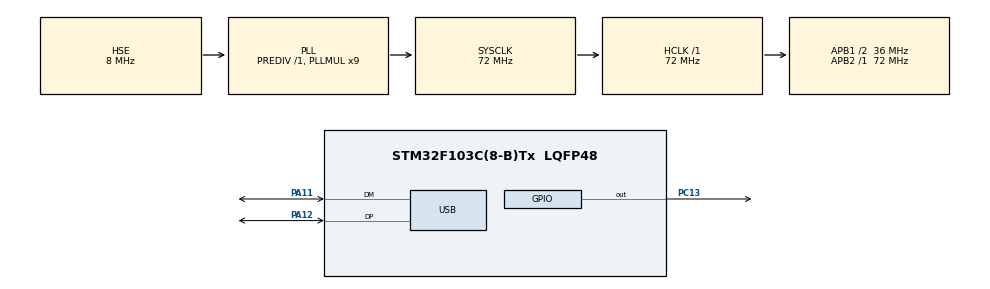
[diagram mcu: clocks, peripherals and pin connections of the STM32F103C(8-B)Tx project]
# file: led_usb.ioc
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FREERTOS.Queues01=receiveQueue,2,128,1,Dynamic,NULL,NULL
FREERTOS.Tasks01=defaultTask,24,128,StartDefaultTask,Default,NULL,Dynamic,NULL,NULL;Taskcmd,24,512,StartTaskcmd,Default,NULL,Dynamic,NULL,NULL
FREERTOS.configTOTAL_HEAP_SIZE=4000
Mcu.Family=STM32F1
Mcu.Name=STM32F103C(8-B)Tx
Mcu.Package=LQFP48
NVIC.PriorityGroup=NVIC_PRIORITYGROUP_4
NVIC.TIM1_UP_IRQn=true\:15\:0\:false\:false\:true\:false\:false\:true\:true
NVIC.TimeBase=TIM1_UP_IRQn
NVIC.TimeBaseIP=TIM1
NVIC.USB_LP_CAN1_RX0_IRQn=true\:5\:0\:false\:false\:true\:true\:false\:true\:true
PA11.Mode=Device
PA11.Signal=USB_DM
PA12.Mode=Device
PA12.Signal=USB_DP
PC13-TAMPER-RTC.Signal=GPIO_Output
PD0-OSC_IN.Mode=HSE-External-Oscillator
PD0-OSC_IN.Signal=RCC_OSC_IN
PD1-OSC_OUT.Mode=HSE-External-Oscillator
PD1-OSC_OUT.Signal=RCC_OSC_OUT
ProjectManager.HeapSize=0x200
ProjectManager.StackSize=0x400
ProjectManager.TargetToolchain=STM32CubeIDE
RCC.AHBFreq_Value=72000000
RCC.APB1CLKDivider=RCC_HCLK_DIV2
RCC.APB1Freq_Value=36000000
RCC.APB1TimFreq_Value=72000000
RCC.APB2Freq_Value=72000000
RCC.APB2TimFreq_Value=72000000
RCC.HCLKFreq_Value=72000000
RCC.PLLMUL=RCC_PLL_MUL9
RCC.SYSCLKFreq_VALUE=72000000
RCC.SYSCLKSource=RCC_SYSCLKSOURCE_PLLCLK
RCC.USBFreq_Value=48000000
RCC.USBPrescaler=RCC_USBCLKSOURCE_PLL_DIV1_5
USB_DEVICE.CLASS_NAME_FS=CDC
USB_DEVICE.VirtualMode=Cdc
USB_DEVICE.VirtualModeFS=Cdc_FS
VP_FREERTOS_VS_CMSIS_V2.Mode=CMSIS_V2
VP_SYS_VS_ND.Mode=No_Debug
VP_SYS_VS_tim1.Mode=TIM1
VP_USB_DEVICE_VS_USB_DEVICE_CDC_FS.Mode=CDC_FS
board=custom

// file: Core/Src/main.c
/* USER CODE BEGIN Header */
/**
  ******************************************************************************
  * @file           : main.c
  * @brief          : Main program body
  ******************************************************************************
  * @attention
  *
  * Copyright (c) 2026 STMicroelectronics.
  * All rights reserved.
  *
  * This software is licensed under terms that can be found in the LICENSE file
  * in the root directory of this software component.
  * If no LICENSE file comes with this software, it is provided AS-IS.
  *
  ******************************************************************************
  */
/* USER CODE END Header */
#include "main.h"
#include "cmsis_os.h"
#include "usb_device.h"
#include "gpio.h"

/* USER CODE BEGIN Includes */
#include "driver_usb.h"

/* USER CODE END Includes */

void SystemClock_Config(void);
void MX_FREERTOS_Init(void);

int main(void)
{

  /* MCU Configuration--------------------------------------------------------*/

  /* Reset of all peripherals, Initializes the Flash interface and the Systick. */
  HAL_Init();

  /* Configure the system clock */
  SystemClock_Config();

  /* Initialize all configured peripherals */
  MX_GPIO_Init();

  /* Init scheduler */
  osKernelInitialize();  /* Call init function for freertos objects (in cmsis_os2.c) */
  MX_FREERTOS_Init();

  /* Start scheduler */
  osKernelStart();

  /* We should never get here as control is now taken by the scheduler */

  /* Infinite loop */
  while (1)
  {

    /* USER CODE BEGIN 3 */
	  read_usb();
  }
  /* USER CODE END 3 */
}

void SystemClock_Config(void)
{
  RCC_OscInitTypeDef RCC_OscInitStruct = {0};
  RCC_ClkInitTypeDef RCC_ClkInitStruct = {0};
  RCC_PeriphCLKInitTypeDef PeriphClkInit = {0};

  /** Initializes the RCC Oscillators according to the specified parameters
  * in the RCC_OscInitTypeDef structure.
  */
  RCC_OscInitStruct.OscillatorType = RCC_OSCILLATORTYPE_HSE;
  RCC_OscInitStruct.HSEState = RCC_HSE_ON;
  RCC_OscInitStruct.HSEPredivValue = RCC_HSE_PREDIV_DIV1;
  RCC_OscInitStruct.HSIState = RCC_HSI_ON;
  RCC_OscInitStruct.PLL.PLLState = RCC_PLL_ON;
  RCC_OscInitStruct.PLL.PLLSource = RCC_PLLSOURCE_HSE;
  RCC_OscInitStruct.PLL.PLLMUL = RCC_PLL_MUL9;
  if (HAL_RCC_OscConfig(&RCC_OscInitStruct) != HAL_OK)
  {
    Error_Handler();
  }

  /** Initializes the CPU, AHB and APB buses clocks
  */
  RCC_ClkInitStruct.ClockType = RCC_CLOCKTYPE_HCLK|RCC_CLOCKTYPE_SYSCLK
                              |RCC_CLOCKTYPE_PCLK1|RCC_CLOCKTYPE_PCLK2;
  RCC_ClkInitStruct.SYSCLKSource = RCC_SYSCLKSOURCE_PLLCLK;
  RCC_ClkInitStruct.AHBCLKDivider = RCC_SYSCLK_DIV1;
  RCC_ClkInitStruct.APB1CLKDivider = RCC_HCLK_DIV2;
  RCC_ClkInitStruct.APB2CLKDivider = RCC_HCLK_DIV1;

  if (HAL_RCC_ClockConfig(&RCC_ClkInitStruct, FLASH_LATENCY_2) != HAL_OK)
  {
    Error_Handler();
  }
  PeriphClkInit.PeriphClockSelection = RCC_PERIPHCLK_USB;
  PeriphClkInit.UsbClockSelection = RCC_USBCLKSOURCE_PLL_DIV1_5;
  if (HAL_RCCEx_PeriphCLKConfig(&PeriphClkInit) != HAL_OK)
  {
    Error_Handler();
  }
}

void HAL_TIM_PeriodElapsedCallback(TIM_HandleTypeDef *htim)
{
  if (htim->Instance == TIM1)
  {
    HAL_IncTick();
  }
}

void Error_Handler(void)
{
  __disable_irq();
  while (1)
  {
  }
}

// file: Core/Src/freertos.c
/* USER CODE BEGIN Header */
/**
  ******************************************************************************
  * File Name          : freertos.c
  * Description        : Code for freertos applications
  ******************************************************************************
  * @attention
  *
  * Copyright (c) 2026 STMicroelectronics.
  * All rights reserved.
  *
  * This software is licensed under terms that can be found in the LICENSE file
  * in the root directory of this software component.
  * If no LICENSE file comes with this software, it is provided AS-IS.
  *
  ******************************************************************************
  */
/* USER CODE END Header */

#include "FreeRTOS.h"
#include "task.h"
#include "main.h"
#include "cmsis_os.h"
#include "driver_usb.h"

/* Definitions for defaultTask */
osThreadId_t defaultTaskHandle;
const osThreadAttr_t defaultTask_attributes = {
  .name = "defaultTask",
  .stack_size = 128 * 4,
  .priority = (osPriority_t) osPriorityNormal,
};
/* Definitions for Taskcmd */
osThreadId_t TaskcmdHandle;
const osThreadAttr_t Taskcmd_attributes = {
  .name = "Taskcmd",
  .stack_size = 512 * 4,
  .priority = (osPriority_t) osPriorityNormal,
};
/* Definitions for receiveQueue */
osMessageQueueId_t receiveQueueHandle;
const osMessageQueueAttr_t receiveQueue_attributes = {
  .name = "receiveQueue"
};

void StartDefaultTask(void *argument);
void StartTaskcmd(void *argument);

extern void MX_USB_DEVICE_Init(void);
void MX_FREERTOS_Init(void); /* (MISRA C 2004 rule 8.1) */

void MX_FREERTOS_Init(void) {

  /* Create the queue(s) */
  /* creation of receiveQueue */
  receiveQueueHandle = osMessageQueueNew (2, 128, &receiveQueue_attributes);

  /* Create the thread(s) */
  /* creation of defaultTask */
  defaultTaskHandle = osThreadNew(StartDefaultTask, NULL, &defaultTask_attributes);

  /* creation of Taskcmd */
  TaskcmdHandle = osThreadNew(StartTaskcmd, NULL, &Taskcmd_attributes);

}

void StartDefaultTask(void *argument)
{
  /* init code for USB_DEVICE */
  MX_USB_DEVICE_Init();
  for(;;)
  {
    osDelay(1);
  }
}

void StartTaskcmd(void *argument)
{
  /* USER CODE BEGIN StartTaskcmd */
  /* Infinite loop */
  for(;;)
  {

	tratar_json(data,len,response);
    osDelay(1);
  }
  /* USER CODE END StartTaskcmd */
}
